AUTOSAR XML (schema 00046)
package /ComponentTypes
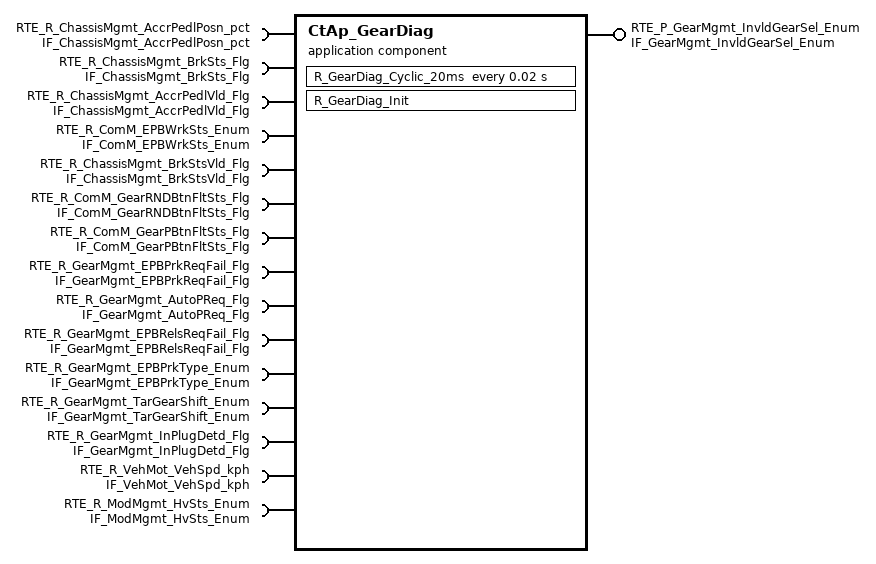
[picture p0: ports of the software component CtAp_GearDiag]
  application sw component type CtAp_GearDiag
    15 x require port:
      RTE_R_ChassisMgmt_AccrPedlPosn_pct: nonqueued-receiver-com-spec{data-element=tec_ChassisMgmt_AccrPedlPosn_pct, filter=data-filter-type=ALWAYS, init-value=0}, required-interface=IF_ChassisMgmt_AccrPedlPosn_pct
      RTE_R_ChassisMgmt_BrkSts_Flg: nonqueued-receiver-com-spec{data-element=tec_ChassisMgmt_BrkSts_Flg, filter=data-filter-type=ALWAYS, init-value=0}, required-interface=IF_ChassisMgmt_BrkSts_Flg
      RTE_R_ChassisMgmt_AccrPedlVld_Flg: nonqueued-receiver-com-spec{data-element=tec_ChassisMgmt_AccrPedlVld_Flg, filter=data-filter-type=ALWAYS, init-value=0}, required-interface=IF_ChassisMgmt_AccrPedlVld_Flg
      RTE_R_ComM_EPBWrkSts_Enum: nonqueued-receiver-com-spec{data-element=tec_ComM_EPBWrkSts_Enum, filter=data-filter-type=ALWAYS, init-value=0}, required-interface=IF_ComM_EPBWrkSts_Enum
      RTE_R_ChassisMgmt_BrkStsVld_Flg: nonqueued-receiver-com-spec{data-element=tec_ChassisMgmt_BrkStsVld_Flg, filter=data-filter-type=ALWAYS, init-value=0}, required-interface=IF_ChassisMgmt_BrkStsVld_Flg
      RTE_R_ComM_GearRNDBtnFltSts_Flg: nonqueued-receiver-com-spec{data-element=tec_ComM_GearRNDBtnFltSts_Flg, filter=data-filter-type=ALWAYS, init-value=0}, required-interface=IF_ComM_GearRNDBtnFltSts_Flg
      RTE_R_ComM_GearPBtnFltSts_Flg: nonqueued-receiver-com-spec{data-element=tec_ComM_GearPBtnFltSts_Flg, filter=data-filter-type=ALWAYS, init-value=0}, required-interface=IF_ComM_GearPBtnFltSts_Flg
      RTE_R_GearMgmt_EPBPrkReqFail_Flg: nonqueued-receiver-com-spec{data-element=tec_GearMgmt_EPBPrkReqFail_Flg, filter=data-filter-type=ALWAYS, init-value=0}, required-interface=IF_GearMgmt_EPBPrkReqFail_Flg
      RTE_R_GearMgmt_AutoPReq_Flg: nonqueued-receiver-com-spec{data-element=tec_GearMgmt_AutoPReq_Flg, filter=data-filter-type=ALWAYS, init-value=0}, required-interface=IF_GearMgmt_AutoPReq_Flg
      RTE_R_GearMgmt_EPBRelsReqFail_Flg: nonqueued-receiver-com-spec{data-element=tec_GearMgmt_EPBRelsReqFail_Flg, filter=data-filter-type=ALWAYS, init-value=0}, required-interface=IF_GearMgmt_EPBRelsReqFail_Flg
      RTE_R_GearMgmt_EPBPrkType_Enum: nonqueued-receiver-com-spec{data-element=tec_GearMgmt_EPBPrkType_Enum, filter=data-filter-type=ALWAYS, init-value=0}, required-interface=IF_GearMgmt_EPBPrkType_Enum
      RTE_R_GearMgmt_TarGearShift_Enum: nonqueued-receiver-com-spec{data-element=tec_GearMgmt_TarGearShift_Enum, filter=data-filter-type=ALWAYS, init-value=0}, required-interface=IF_GearMgmt_TarGearShift_Enum
      RTE_R_GearMgmt_InPlugDetd_Flg: nonqueued-receiver-com-spec{data-element=tec_GearMgmt_InPlugDetd_Flg, filter=data-filter-type=ALWAYS, init-value=0}, required-interface=IF_GearMgmt_InPlugDetd_Flg
      RTE_R_VehMot_VehSpd_kph: nonqueued-receiver-com-spec{data-element=tec_VehMot_VehSpd_kph, filter=data-filter-type=ALWAYS, init-value=0}, required-interface=IF_VehMot_VehSpd_kph
      RTE_R_ModMgmt_HvSts_Enum: nonqueued-receiver-com-spec{data-element=tec_ModMgmt_HvSts_Enum, filter=data-filter-type=ALWAYS, init-value=0}, required-interface=IF_ModMgmt_HvSts_Enum
    provide port RTE_P_GearMgmt_InvldGearSel_Enum: nonqueued-sender-com-spec{data-element=tec_GearMgmt_InvldGearSel_Enum, init-value=0}, provided-interface=IF_GearMgmt_InvldGearSel_Enum
    behavior CtAp_GearDiag_InternalBehavior
      init event CtAp_GearDiag_InitEvent: start-on-event=R_GearDiag_Init
      timing event TMT_R_GearDiag_Cyclic_20ms: start-on-event=R_GearDiag_Cyclic_20ms, period=0.02
      runnable R_GearDiag_Init
      runnable R_GearDiag_Cyclic_20ms
        data-receive-point-by-arguments:
          15 x access:
            REC_RTE_R_ChassisMgmt_AccrPedlPosn_pct_tec_ChassisMgmt_AccrPedlPosn_pct: accessed-variable=RTE_R_ChassisMgmt_AccrPedlPosn_pct.tec_ChassisMgmt_AccrPedlPosn_pct
            REC_RTE_R_ChassisMgmt_AccrPedlVld_Flg_tec_ChassisMgmt_AccrPedlVld_Flg: accessed-variable=RTE_R_ChassisMgmt_AccrPedlVld_Flg.tec_ChassisMgmt_AccrPedlVld_Flg
            REC_RTE_R_ChassisMgmt_BrkStsVld_Flg_tec_ChassisMgmt_BrkStsVld_Flg: accessed-variable=RTE_R_ChassisMgmt_BrkStsVld_Flg.tec_ChassisMgmt_BrkStsVld_Flg
            REC_RTE_R_ChassisMgmt_BrkSts_Flg_tec_ChassisMgmt_BrkSts_Flg: accessed-variable=RTE_R_ChassisMgmt_BrkSts_Flg.tec_ChassisMgmt_BrkSts_Flg
            REC_RTE_R_ComM_EPBWrkSts_Enum_tec_ComM_EPBWrkSts_Enum: accessed-variable=RTE_R_ComM_EPBWrkSts_Enum.tec_ComM_EPBWrkSts_Enum
            REC_RTE_R_ComM_GearPBtnFltSts_Flg_tec_ComM_GearPBtnFltSts_Flg: accessed-variable=RTE_R_ComM_GearPBtnFltSts_Flg.tec_ComM_GearPBtnFltSts_Flg
            REC_RTE_R_ComM_GearRNDBtnFltSts_Flg_tec_ComM_GearRNDBtnFltSts_Flg: accessed-variable=RTE_R_ComM_GearRNDBtnFltSts_Flg.tec_ComM_GearRNDBtnFltSts_Flg
            REC_RTE_R_GearMgmt_AutoPReq_Flg_tec_GearMgmt_AutoPReq_Flg: accessed-variable=RTE_R_GearMgmt_AutoPReq_Flg.tec_GearMgmt_AutoPReq_Flg
            REC_RTE_R_GearMgmt_EPBPrkReqFail_Flg_tec_GearMgmt_EPBPrkReqFail_Flg: accessed-variable=RTE_R_GearMgmt_EPBPrkReqFail_Flg.tec_GearMgmt_EPBPrkReqFail_Flg
            REC_RTE_R_GearMgmt_EPBPrkType_Enum_tec_GearMgmt_EPBPrkType_Enum: accessed-variable=RTE_R_GearMgmt_EPBPrkType_Enum.tec_GearMgmt_EPBPrkType_Enum
            REC_RTE_R_GearMgmt_EPBRelsReqFail_Flg_tec_GearMgmt_EPBRelsReqFail_Flg: accessed-variable=RTE_R_GearMgmt_EPBRelsReqFail_Flg.tec_GearMgmt_EPBRelsReqFail_Flg
            REC_RTE_R_GearMgmt_InPlugDetd_Flg_tec_GearMgmt_InPlugDetd_Flg: accessed-variable=RTE_R_GearMgmt_InPlugDetd_Flg.tec_GearMgmt_InPlugDetd_Flg
            REC_RTE_R_GearMgmt_TarGearShift_Enum_tec_GearMgmt_TarGearShift_Enum: accessed-variable=RTE_R_GearMgmt_TarGearShift_Enum.tec_GearMgmt_TarGearShift_Enum
            REC_RTE_R_ModMgmt_HvSts_Enum_tec_ModMgmt_HvSts_Enum: accessed-variable=RTE_R_ModMgmt_HvSts_Enum.tec_ModMgmt_HvSts_Enum
            REC_RTE_R_VehMot_VehSpd_kph_tec_VehMot_VehSpd_kph: accessed-variable=RTE_R_VehMot_VehSpd_kph.tec_VehMot_VehSpd_kph
        data-send-points:
          access SEND_RTE_P_GearMgmt_InvldGearSel_Enum_tec_GearMgmt_InvldGearSel_Enum: accessed-variable=RTE_P_GearMgmt_InvldGearSel_Enum.tec_GearMgmt_InvldGearSel_Enum
  swc implementation CtAp_GearDiag_Implementation: behavior=CtAp_GearDiag_InternalBehavior
    code-descriptors:
      code Default: artifact-descriptors=autosar-engineering-object=category=SWOBJ
